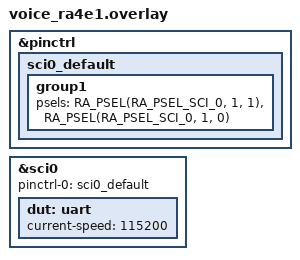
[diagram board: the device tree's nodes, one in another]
/*
 * Copyright (c) 2025 Renesas Electronics Corporation
 * SPDX-License-Identifier: Apache-2.0
 */

&pinctrl {
	sci0_default: sci0_default {
		group1 {
			/* tx rx */
			psels = <RA_PSEL(RA_PSEL_SCI_0, 1, 1)>,
			<RA_PSEL(RA_PSEL_SCI_0, 1, 0)>;
		};
	};
};

&sci0 {
	pinctrl-0 = <&sci0_default>;
	pinctrl-names = "default";
	status = "okay";
	dut: uart {
		current-speed = <115200>;
		status = "okay";
	};
};
